# MSP430G2231 register map
Registers are 8-bit, read-write, reset 0x0 unless marked. A register's access mark holds for its fields unless they carry their own. Offsets are from the block's base; [hi:lo] are bit positions; 'fields as' and 'values as' point back to an identical list.

## CALIBRATION_DATA
Base 0x000010FE
0x00 CALDCO_1MHZ — DCOCTL Calibration Data for 1MHz
  [7:0] CALDCO_1MHZ — DCOCTL Calibration Data register
0x01 CALBC1_1MHZ — BCSCTL1 Calibration Data for 1MHz
  [7:0] CALBC1_1MHZ — BCSCTL1 Calibration Data register

## WATCHDOG_TIMER
Base 0x00000120
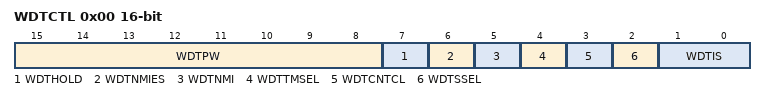
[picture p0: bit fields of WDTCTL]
0x00 WDTCTL 16-bit — Watchdog Timer Control
  [15:8] WDTPW — Watchdog Timer Password
    on read: 105=PASSWORD (Value always read from the Watchdog Password register) | on write: 90=PASSWORD (Value which must be written to the Watchdog Password register)
  [7] WDTHOLD
  [6] WDTNMIES
  [5] WDTNMI
  [4] WDTTMSEL
  [3] WDTCNTCL
  [2] WDTSSEL
  [1:0] WDTIS — WDTIS0

## FLASH
Base 0x00000128
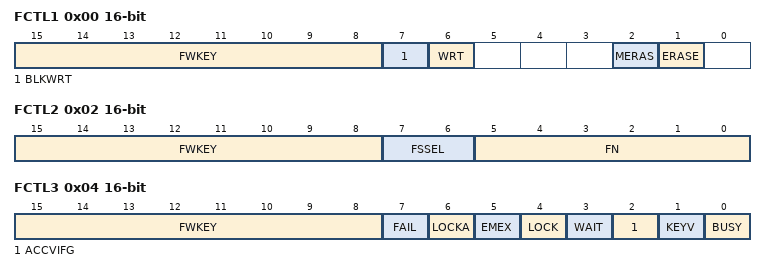
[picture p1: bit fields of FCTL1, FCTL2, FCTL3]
0x00 FCTL1 16-bit — FLASH Control 1
  [15:8] FWKEY — FCTL1 Password
    on read: 150=PASSWORD (Value always read from the FCTL1 Password register) | on write: 165=PASSWORD (Value which must be written to the FCTL1 Password register)
  [7] BLKWRT — Enable bit for Flash segment write
  [6] WRT — Enable bit for Flash write
  [2] MERAS — Enable bit for Flash mass erase
  [1] ERASE — Enable bit for Flash segment erase
0x02 FCTL2 16-bit — FLASH Control 2
  [15:8] FWKEY — FCTL2 Password
    on read: 150=PASSWORD (Value always read from the FCTL2 Password register) | on write: 165=PASSWORD (Value which must be written to the FCTL2 Password register)
  [7:6] FSSEL — Flash clock select 0 */ /* to distinguish from USART SSELx
    0=Flash clock select: 0 - ACLK; 1=Flash clock select: 1 - MCLK; 2=Flash clock select: 2 - SMCLK; 3=Flash clock select: 3 - SMCLK
  [5:0] FN — Divide Flash clock by 1 to 64 using FN0 to FN5 according to:
0x04 FCTL3 16-bit — FLASH Control 3
  [15:8] FWKEY — FCTL3 Password
    on read: 150=PASSWORD (Value always read from the FCTL3 Password register) | on write: 165=PASSWORD (Value which must be written to the FCTL3 Password register)
  [7] FAIL — Last Program or Erase failed
  [6] LOCKA — Segment A Lock bit: read = 1 - Segment is locked (read only)
  [5] EMEX — Flash Emergency Exit
  [4] LOCK — Lock bit: 1 - Flash is locked (read only)
  [3] WAIT — Wait flag for segment write
  [2] ACCVIFG — Flash Access violation flag
  [1] KEYV — Flash Key violation flag
  [0] BUSY — Flash busy: 1

## TIMER_A2
Base 0x0000012E
0x00 TAIV 16-bit — Timer A Interrupt Vector Word
  [3:0] TAIV — Timer A Interrupt Vector value
    0=NONE (No interrupt pending); 2=TACCR1 (Capture/Compare 1); 10=TAIFG (Timer overflow)
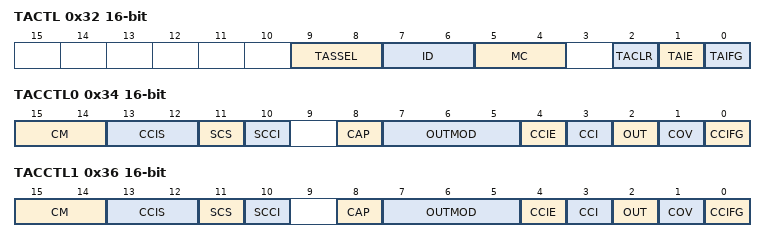
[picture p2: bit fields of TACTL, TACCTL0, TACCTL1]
0x32 TACTL 16-bit — Timer A Control
  [9:8] TASSEL — Timer A clock source select 1
    0=TACLK; 1=ACLK; 2=SMCLK; 3=INCLK (INCLK (device specific, often assigned to the inverted TBCLK))
  [7:6] ID — Timer A clock input divider 1
    0=DIV_1 (/1); 1=DIV_2 (/2); 2=DIV_4 (/4); 3=DIV_8 (/8)
  [5:4] MC — Timer A mode control 1
    0=STOP (Stop mode: the timer is halted); 1=UP (Up mode: the timer counts up to TACCR0); 2=CONTINUOUS (Continous mode: the timer counts up to 0xFFFF); 3=UP_DOWN (Up/down mode: the timer counts up to TACCR0 then down to 0x0000)
  [2] TACLR — Timer A counter clear
  [1] TAIE — Timer A counter interrupt enable
  [0] TAIFG — Timer A counter interrupt flag
0x34 TACCTL0 16-bit — Timer A Capture/Compare Control 0
  [15:14] CM — Capture mode 1
    0=NONE (No capture); 1=RISING (Capture on rising edge); 2=FALLING (Capture on falling edge); 3=BOTH (Capture on both rising and falling edges)
  [13:12] CCIS — Capture input select 1
    0=CCI0A; 1=CCI0B; 2=GND; 3=VCC
  [11] SCS — Capture sychronize
  [10] SCCI — Latched capture signal (read)
  [8] CAP — Capture mode: 1 /Compare mode : 0
  [7:5] OUTMOD — Output mode 2
    0=OUT (OUT bit value); 1=SET; 2=TOGGLE_RESET; 3=SET_RESET; 4=TOGGLE; 5=RESET; 6=TOGGLE_SET; 7=RESET_SET
  [4] CCIE — Capture/compare interrupt enable
  [3] CCI — Capture input signal (read)
  [2] OUT — PWM Output signal if output mode 0
  [1] COV — Capture/compare overflow flag
  [0] CCIFG — Capture/compare interrupt flag
0x36 TACCTL1 16-bit — Timer A Capture/Compare Control 1
  fields as TACCTL0
0x42 TAR 16-bit — Timer A Counter Register
0x44 TACCR0 16-bit — Timer A Capture/Compare 0
  [15:0] TACCR0 — Timer A Capture/Compare register 0
0x46 TACCR1 16-bit — Timer A Capture/Compare 1
  [15:0] TACCR1 — Timer A Capture/Compare register 1
